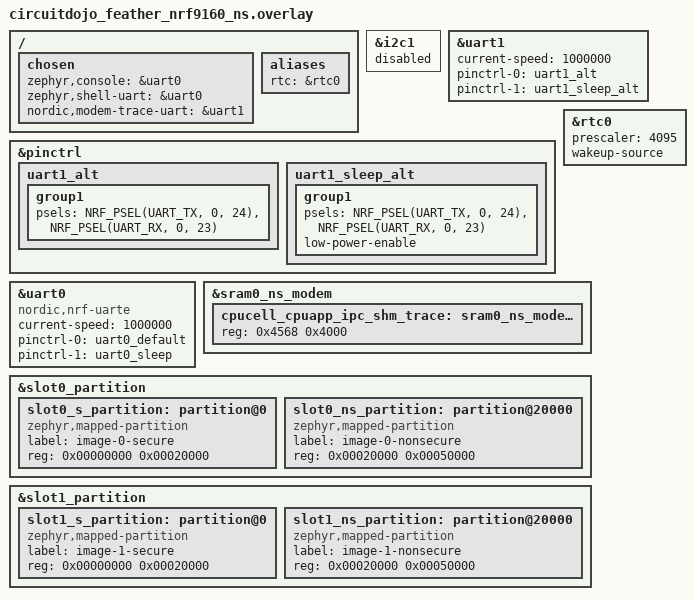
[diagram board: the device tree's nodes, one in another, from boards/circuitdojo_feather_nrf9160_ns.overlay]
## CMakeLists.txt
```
cmake_minimum_required(VERSION 3.20.0)

# This sample verifies the platform's certificate chain.
set(SAMPLE_TLS verify)
include(${CMAKE_CURRENT_SOURCE_DIR}/../common/app.cmake)

find_package(Zephyr REQUIRED HINTS $ENV{ZEPHYR_BASE})
project(https_init)

include(${CMAKE_CURRENT_SOURCE_DIR}/../common/cert.cmake)

target_sources(app PRIVATE src/main.c src/shadow.c)

include(${CMAKE_CURRENT_SOURCE_DIR}/../common/net.cmake)
```

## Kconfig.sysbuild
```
rsource "../Kconfig.sysbuild.signing"

# native_sim has no bootloader or second slot; every other board boots through
# MCUboot, which is where FOTA stages an image.
choice BOOTLOADER
	default BOOTLOADER_NONE if BOARD_NATIVE_SIM
	default BOOTLOADER_MCUBOOT
endchoice

source "share/sysbuild/Kconfig"
```

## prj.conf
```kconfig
# HTTPS connector, remote log upload and FOTA through MCUboot. The endpoint
# and token belong in the git-ignored prj.local.conf.
CONFIG_PIGEON=y
CONFIG_PIGEON_CONNECTOR_HTTPS=y
# The modem's credential store outlives a reflash and is keyed by tag, so each
# sample here owns a distinct one rather than the shared default.
CONFIG_PIGEON_HTTPS_SEC_TAG=42
CONFIG_PIGEON_LOG_UPLOAD=y
CONFIG_PIGEON_FOTA=y

# Image management, the path FOTA stages an image through.
CONFIG_BOOTLOADER_MCUBOOT=y
CONFIG_MCUBOOT_BOOTUTIL_LIB=y
CONFIG_FLASH=y
CONFIG_FLASH_MAP=y
CONFIG_FLASH_PAGE_LAYOUT=y
CONFIG_STREAM_FLASH=y
CONFIG_IMG_MANAGER=y
CONFIG_IMG_ERASE_PROGRESSIVELY=y
CONFIG_IMG_ENABLE_IMAGE_CHECK=y
CONFIG_SETTINGS=y

CONFIG_PICOLIBC=y
CONFIG_STD_C17=y
CONFIG_MISRA_SANE=y
CONFIG_DEBUG=y
CONFIG_DEBUG_OPTIMIZATIONS=y

CONFIG_HEAP_MEM_POOL_SIZE=8192
CONFIG_MAIN_STACK_SIZE=8192
CONFIG_SYSTEM_WORKQUEUE_STACK_SIZE=4096
# Logging from the connection manager's event callbacks overflows the default.
CONFIG_NET_MGMT_EVENT_STACK_SIZE=2048

CONFIG_NETWORKING=y
CONFIG_NET_SOCKETS=y
CONFIG_NET_SOCKETS_SOCKOPT_TLS=y
CONFIG_NET_IPV4=y
CONFIG_NET_IPV6=y
CONFIG_NET_CONNECTION_MANAGER=y
CONFIG_NET_CONNECTION_MANAGER_MONITOR_STACK_SIZE=1024

CONFIG_LOG=y
CONFIG_LOG_DEFAULT_LEVEL=3
CONFIG_LOG_MODE_IMMEDIATE=y
# Lets the shadow's "log" field silence and restore logging at runtime.
CONFIG_LOG_RUNTIME_FILTERING=y
CONFIG_NET_LOG=y
CONFIG_NET_SOCKETS_LOG_LEVEL_DBG=y
```

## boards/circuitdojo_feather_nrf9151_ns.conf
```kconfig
# nRF9151 Feather counterpart to circuitdojo_feather_nrf9160_ns.conf. Content
# is identical -- nothing here is 9160-specific (modem key mgmt, TF-M build
# mode, UART async config, modem trace backend selection, boot banner all
# apply the same way to any nRF91-series board using the modem-offloaded
# TLS + TF-M split), so this is a straight mirror of that file rather than a
# copy this board needed to diverge from.

# NCS boot banner
CONFIG_NCS_APPLICATION_BOOT_BANNER_STRING="Pigeon"

# Allow writing to the (internal) flash at runtime, needed for MCUmgr image
# management to write firmware updates into slot1.
CONFIG_MPU_ALLOW_FLASH_WRITE=y

# Align the max FD entry to NRF_MODEM_MAX_SOCKET_COUNT(8)
CONFIG_ZVFS_OPEN_MAX=8
CONFIG_NET_SOCKETS_POLL_MAX=8

# Disable Duplicate Address Detection (DAD)
# due to not being properly implemented for offloaded interfaces.
CONFIG_NET_IPV6_NBR_CACHE=n
CONFIG_NET_IPV6_MLD=n

# Connection Manager and Connectivity layer
CONFIG_NRF_MODEM_LIB_NET_IF=y

# AT Host
CONFIG_UART_INTERRUPT_DRIVEN=y
CONFIG_AT_HOST_LIBRARY=y

# Modem key management
# Must be y: nRF91 TLS sockets are offloaded to the modem, which does its own
# TLS handshake using certs provisioned to ITS OWN credential store via AT
# commands (modem_key_mgmt), not Zephyr's tls_credentials/mbedTLS subsystem.
# With this =n, connection_manager.c's provision_cert() fell through to
# tls_credential_add(), which the offloaded socket implementation never
# consults -- so the modem had no CA cert at the sec_tag and any outbound TLS
# connection (e.g. the pigeon HTTPS shadow fetch) would fail the handshake.
CONFIG_MODEM_KEY_MGMT=y

# TF-M configurations
# TF-M's secure image size/RAM (slot0_s_partition, sram0_s) is now set via the
# board devicetree overlay instead of Partition Manager Kconfig.
CONFIG_BUILD_WITH_TFM=y
CONFIG_TFM_PROFILE_TYPE_NOT_SET=y
CONFIG_TFM_CMAKE_BUILD_TYPE_RELEASE=y

# UART configuration (common)
CONFIG_SERIAL=y
CONFIG_UART_ASYNC_API=y

# UART configuration (nRF91 specific)
CONFIG_UART_1_ASYNC=y
CONFIG_UART_1_INTERRUPT_DRIVEN=n

# Modem trace uart backend
# NRF_MODEM_LIB_TRACE_BACKEND_UART lives under "if NRF_MODEM_LIB_TRACE", so the
# trace subsystem itself must be enabled or the backend choice never applies.
CONFIG_NRF_MODEM_LIB_TRACE=y
CONFIG_NRF_MODEM_LIB_TRACE_BACKEND_UART=y

# Keeps the MCUboot secondary/OTA slot non-secure at the SPU level, so a
# FOTA write from the non-secure app doesn't fault.
# This board's own devicetree (Circuit Dojo upstream) declares an onboard SPI-NOR
# chip via `nordic,pm-ext-flash = &w25q128jv` (for its littlefs partition, NOT
# MCUboot). That alone flips PM_EXTERNAL_FLASH_ENABLED=y, which flips this
# symbol's Kconfig default to y (nrf/subsys/partition_manager/Kconfig:
# `default y if BOOTLOADER_MCUBOOT`), which SKIPS the NRF_NS_SECONDARY=y
# auto-configuration in nrf/modules/trusted-firmware-m/CMakeLists.txt (guarded on
# `NOT PM_EXTERNAL_FLASH_MCUBOOT_SECONDARY`). With NRF_NS_SECONDARY off, TF-M
# leaves the ENTIRE secondary/OTA slot Secure at the SPU level, so the non-secure
# FOTA client's write to slot1 (0x80000) is a TrustZone attribution-unit
# violation -> Secure Fault -> halt. We do NOT put the MCUboot secondary slot in
# external flash (it's the same internal flash as slot0), so force this off. The
# 9160 doesn't need this: its board dtsi has no `nordic,pm-ext-flash`, so the
# Kconfig default never fires.
CONFIG_PM_EXTERNAL_FLASH_MCUBOOT_SECONDARY=n
```

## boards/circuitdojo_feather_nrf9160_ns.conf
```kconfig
# Beyond ../../common/boards/nrf91.conf.

# What this build reports as its running firmware; bump it with each release.
CONFIG_PIGEON_FOTA_CURRENT_VERSION="0.1.0"
# The nRF Connect SDK dfu_target backend, which the modem and MCUboot
# integration are built around.
CONFIG_PIGEON_FOTA_NCS=y

# FOTA resume and the attempt budget both persist state; without a backend
# behind CONFIG_SETTINGS they disappear from the build rather than fail it.
CONFIG_NVS=y
CONFIG_SETTINGS_NVS=y
# One shadow target is chased a bounded number of times, so an image that
# boot-loops cannot re-download itself forever.
CONFIG_PIGEON_FOTA_ATTEMPT_BUDGET=y

# Image upload over the console UART (newtmgr -c serial) as a FOTA fallback.
CONFIG_BASE64=y
CONFIG_CRC=y
CONFIG_ZCBOR=y
CONFIG_MCUMGR=y
CONFIG_UART_MCUMGR=y
CONFIG_MCUMGR_TRANSPORT_UART=y
CONFIG_MCUMGR_GRP_IMG=y
CONFIG_MCUMGR_GRP_OS=y

# Modem trace on uart1 (see the overlay); the backend choice only applies
# once the trace subsystem itself is on.
CONFIG_NRF_MODEM_LIB_TRACE=y
CONFIG_NRF_MODEM_LIB_TRACE_BACKEND_UART=y
CONFIG_UART_1_ASYNC=y
CONFIG_UART_1_INTERRUPT_DRIVEN=n
```

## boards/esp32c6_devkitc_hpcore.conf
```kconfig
# Beyond ../../common/boards/esp32c6.conf.

# What this build reports as its running firmware; bump it with each release.
# Here, not prj.conf: native_sim builds with FOTA off, and assigning a symbol
# whose dependencies are unmet fails the build.
CONFIG_PIGEON_FOTA_CURRENT_VERSION="0.1.0"

# One TLS connection per Range chunk costs about nine seconds here; 32 KiB
# chunks fetch an 800 KiB image in about 25 of them.
CONFIG_PIGEON_FOTA_CHUNK_SIZE=32768
# A long download can still fail a WiFi-adapter allocation inside a fatal
# ESP_ERROR_CHECK; a reboot there resumes from the persisted offset.
CONFIG_PIGEON_REBOOT_ON_FATAL=y
CONFIG_PIGEON_FOTA_RESUME=y
# One shadow target is chased a bounded number of times, so an image that
# boot-loops cannot re-download itself forever.
CONFIG_PIGEON_FOTA_ATTEMPT_BUDGET=y
# The resume offset and attempt count persist in settings over NVS.
CONFIG_MCUBOOT_IMG_MANAGER=y
CONFIG_NVS=y
CONFIG_SETTINGS_NVS=y
```

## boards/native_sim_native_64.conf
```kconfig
# Beyond ../../common/boards/native_sim.conf.

# No bootloader or second slot on the host, so no FOTA or image management.
CONFIG_PIGEON_FOTA=n
CONFIG_BOOTLOADER_MCUBOOT=n
CONFIG_MCUBOOT_BOOTUTIL_LIB=n
CONFIG_IMG_MANAGER=n
CONFIG_IMG_ERASE_PROGRESSIVELY=n
CONFIG_IMG_ENABLE_IMAGE_CHECK=n
```

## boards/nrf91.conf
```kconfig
# Both nRF91 Feathers, on top of ../../common/boards/nrf91.conf.

# What this build reports as its running firmware; bump it with each release.
# Here, not prj.conf: native_sim builds with FOTA off, and assigning a symbol
# whose dependencies are unmet fails the build.
CONFIG_PIGEON_FOTA_CURRENT_VERSION="0.1.0"
# The nRF Connect SDK dfu_target backend, which the modem and MCUboot
# integration are built around.
CONFIG_PIGEON_FOTA_NCS=y

# The nRF Connect SDK banner only exists where a VERSION file does, and it
# otherwise announces itself as "My Application".
CONFIG_NCS_APPLICATION_BOOT_BANNER_STRING="Pigeon"

# FOTA resume and the attempt budget both persist state; without a backend
# behind CONFIG_SETTINGS they disappear from the build rather than fail it.
CONFIG_NVS=y
CONFIG_SETTINGS_NVS=y
# One shadow target is chased a bounded number of times, so an image that
# boot-loops cannot re-download itself forever.
CONFIG_PIGEON_FOTA_ATTEMPT_BUDGET=y

# Modem trace on uart1 (see the overlay); the backend choice only applies
# once the trace subsystem itself is on.
CONFIG_NRF_MODEM_LIB_TRACE=y
CONFIG_NRF_MODEM_LIB_TRACE_BACKEND_UART=y
CONFIG_UART_1_ASYNC=y
CONFIG_UART_1_INTERRUPT_DRIVEN=n
```

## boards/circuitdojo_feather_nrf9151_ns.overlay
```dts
/* Modem trace UART; this board's own partition file already carves out the
 * trace buffer, and its i2c1 is disabled by default. */
&uart1 {
  status = "okay";
  current-speed = <1000000>;
};

&uart0 {
  status = "okay";
  compatible = "nordic,nrf-uarte";
  current-speed = <115200>;
  pinctrl-0 = <&uart0_default>;
  pinctrl-1 = <&uart0_sleep>;
  pinctrl-names = "default", "sleep";
};

/* The stock 256/192 KiB secure/non-secure split leaves TF-M most of its
 * share unused while this application overflows its own. The slot total is
 * unchanged, so MCUboot's overlay needs nothing. */
/delete-node/ &slot0_s_partition;
/delete-node/ &slot0_ns_partition;

&slot0_partition {
  slot0_s_partition: partition@0 {
    compatible = "zephyr,mapped-partition";
    label = "image-0-secure";
    reg = <0x00000000 0x00020000>;
  };

  slot0_ns_partition: partition@20000 {
    compatible = "zephyr,mapped-partition";
    label = "image-0-nonsecure";
    reg = <0x00020000 0x00050000>;
  };
};

/delete-node/ &slot1_s_partition;
/delete-node/ &slot1_ns_partition;

&slot1_partition {
  slot1_s_partition: partition@0 {
    compatible = "zephyr,mapped-partition";
    label = "image-1-secure";
    reg = <0x00000000 0x00020000>;
  };

  slot1_ns_partition: partition@20000 {
    compatible = "zephyr,mapped-partition";
    label = "image-1-nonsecure";
    reg = <0x00020000 0x00050000>;
  };
};

/ {
  chosen {
    zephyr,console = &uart0;
    zephyr,shell-uart = &uart0;
    nordic,modem-trace-uart = &uart1;
  };
};
```

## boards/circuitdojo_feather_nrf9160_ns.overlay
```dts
/* i2c1 shares its peripheral instance with the trace UART below. */
&i2c1 {
    status = "disabled";
};

/* Modem trace UART. */
&uart1 {
    status = "okay";
    current-speed = <1000000>;
    pinctrl-0 = <&uart1_alt>;
    pinctrl-1 = <&uart1_sleep_alt>;
    pinctrl-names = "default", "sleep";
};

&pinctrl {
    uart1_alt: uart1_alt {
        group1 {
            psels = <NRF_PSEL(UART_TX, 0, 24)>,
                <NRF_PSEL(UART_RX, 0, 23)>;
        };
    };

    uart1_sleep_alt: uart1_sleep_alt {
        group1 {
            psels = <NRF_PSEL(UART_TX, 0, 24)>,
                <NRF_PSEL(UART_RX, 0, 23)>;
            low-power-enable;
        };
    };
};

&uart0 {
  status = "okay";
  compatible = "nordic,nrf-uarte";
  current-speed = <1000000>;
  pinctrl-0 = <&uart0_default>;
  pinctrl-1 = <&uart0_sleep>;
  pinctrl-names = "default", "sleep";
};

&rtc0 {
  status = "okay";
  /* 32768 Hz / (4095 + 1) = 8 Hz. */
  prescaler = <4095>;
  wakeup-source;
};

/* The modem trace buffer fits in the slack the stock partition file leaves
 * inside the modem shared-memory region, so nothing else has to move.
 * Nordic's own modem-trace snippet sizes it for a different SRAM total and
 * overflows this board. */
&sram0_ns_modem {
  cpucell_cpuapp_ipc_shm_trace: sram0_ns_modem@4568 {
    reg = <0x4568 0x4000>;
  };
};

/* The stock 256/192 KiB secure/non-secure split leaves TF-M most of its
 * share unused while this application overflows its own. The slot total is
 * unchanged, so MCUboot's overlay needs nothing. */
/delete-node/ &slot0_s_partition;
/delete-node/ &slot0_ns_partition;

&slot0_partition {
  slot0_s_partition: partition@0 {
    compatible = "zephyr,mapped-partition";
    label = "image-0-secure";
    reg = <0x00000000 0x00020000>;
  };

  slot0_ns_partition: partition@20000 {
    compatible = "zephyr,mapped-partition";
    label = "image-0-nonsecure";
    reg = <0x00020000 0x00050000>;
  };
};

/delete-node/ &slot1_s_partition;
/delete-node/ &slot1_ns_partition;

&slot1_partition {
  slot1_s_partition: partition@0 {
    compatible = "zephyr,mapped-partition";
    label = "image-1-secure";
    reg = <0x00000000 0x00020000>;
  };

  slot1_ns_partition: partition@20000 {
    compatible = "zephyr,mapped-partition";
    label = "image-1-nonsecure";
    reg = <0x00020000 0x00050000>;
  };
};

/ {
  chosen {
    zephyr,console = &uart0;
    zephyr,shell-uart = &uart0;
    nordic,modem-trace-uart = &uart1;
  };

  aliases {
    rtc = &rtc0;
  };
};
```

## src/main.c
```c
#include <pigeon.h>
#include <zephyr/kernel.h>

#include "net_connect.h"
#include "shadow.h"

/* The platform's root CA, terminated because mbedTLS parses PEM as a string. */
static const char ca_cert[] = {
#include "GTS_Root_R4.crt.hex"
    0x00
};

BUILD_ASSERT(sizeof(ca_cert) < KB(4), "the modem's credential store caps a certificate at 4 KiB");

int main(void) {
  int err = net_prepare();

  if (err) {
    return err;
  }

  err = net_install_ca(CONFIG_PIGEON_HTTPS_SEC_TAG, ca_cert, sizeof(ca_cert));
  if (err) {
    return err;
  }

  err = net_connect();
  if (err) {
    return err;
  }

  /* The endpoint and token come from Kconfig. device_id only names this
   * device in its own logs; the platform identifies it by its token. */
  struct pigeon_config config = {
      .device_id = "pigeon-sample",
      .connector = {.type = PIGEON_CONNECTOR_HTTPS},
  };

  err = pigeon_init(&config);
  if (err) {
    net_disconnect();
    return err;
  }

  shadow_loop();

  return net_disconnect();
}
```

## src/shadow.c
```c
/** @headerfile shadow.h */
#include "shadow.h"

#include <pigeon.h>
#include <string.h>
#include <zephyr/data/json.h>
#include <zephyr/kernel.h>
#include <zephyr/logging/log.h>
#include <zephyr/logging/log_ctrl.h>
#include <zephyr/sys/printk.h>

#include "net_connect.h"

LOG_MODULE_REGISTER(shadow);

/* target_config is opaque JSON to the library; this application decides what
 * its keys mean. "firmware" decodes into the struct pigeon_fota_apply() takes. */
struct app_shadow_config {
  bool log;
  int telemetry_interval;
  bool reboot;
#if defined(CONFIG_PIGEON_FOTA)
  struct pigeon_fota_info firmware;
#endif
};

#if defined(CONFIG_PIGEON_FOTA)
static const struct json_obj_descr app_firmware_descr[] = {
    JSON_OBJ_DESCR_PRIM(struct pigeon_fota_info, version, JSON_TOK_STRING_BUF),
    JSON_OBJ_DESCR_PRIM(struct pigeon_fota_info, size, JSON_TOK_NUMBER),
    JSON_OBJ_DESCR_PRIM(struct pigeon_fota_info, sha256, JSON_TOK_STRING_BUF),
};
#endif

static const struct json_obj_descr app_shadow_config_descr[] = {
    JSON_OBJ_DESCR_PRIM(struct app_shadow_config, log, JSON_TOK_TRUE),
    JSON_OBJ_DESCR_PRIM(struct app_shadow_config, telemetry_interval, JSON_TOK_NUMBER),
    JSON_OBJ_DESCR_PRIM(struct app_shadow_config, reboot, JSON_TOK_TRUE),
#if defined(CONFIG_PIGEON_FOTA)
    JSON_OBJ_DESCR_OBJECT(struct app_shadow_config, firmware, app_firmware_descr),
#endif
};

/* Defaults applied before the first sync of a boot. Nothing persists across
 * reboots, so every boot re-applies the platform's target from here.
 * firmware.version starts at this build's own version, which is what lets a
 * freshly booted image report itself as converged with no bookkeeping. */
static struct app_shadow_config current_config = {
    .log = false,
    .telemetry_interval = 60,
    .reboot = false,
#if defined(CONFIG_PIGEON_FOTA)
    .firmware = {.version = CONFIG_PIGEON_FOTA_CURRENT_VERSION, .size = 0, .sha256 = ""},
#endif
};

/* One call covers every module, so the shadow's "log" field really silences
 * and restores output. */
static void set_all_log_levels(uint32_t level) {
  uint32_t module_count = log_src_cnt_get(Z_LOG_LOCAL_DOMAIN_ID);

  for (uint32_t i = 0; i < module_count; i++) {
    log_filter_set(NULL, Z_LOG_LOCAL_DOMAIN_ID, (int16_t)i, level);
  }
}

/* Both keys ride one telemetry POST. poll_count restarting at 1 doubles as a
 * reboot indicator on the dashboard. */
static void report_telemetry(void) {
  static unsigned int poll_count;
  char buf[21];

  snprintk(buf, sizeof(buf), "%lld", (long long)(k_uptime_get() / 1000));

  int err = pigeon_telemetry_set("uptime_s", buf);

  snprintk(buf, sizeof(buf), "%u", ++poll_count);

  if (!err) {
    err = pigeon_telemetry_set("poll_count", buf);
  }

  if (!err) {
    err = pigeon_telemetry_flush();
  }

  if (err) {
    LOG_WRN("Telemetry report failed: %d", err);
  }
}

int shadow_sync(void) {
  struct pigeon_shadow_doc doc;
  int err = pigeon_shadow_get(&doc);

  if (err) {
    LOG_ERR("Failed to fetch device shadow: %d", err);
    return err;
  }

  LOG_INF(
      "Shadow fetched: target_version=%d current_version=%d updated_at=%lld", doc.target_version,
      doc.current_version, doc.updated_at
  );

#if defined(CONFIG_PIGEON_FOTA)
  /* A successful fetch is this application's definition of a healthy boot.
   * Runs before the convergence check so a new image that lands already
   * converged is still confirmed; a no-op once confirmed. */
  pigeon_fota_confirm_boot();
#endif

  report_telemetry();

  if (doc.target_version == doc.current_version) {
    LOG_INF("Shadow already converged at version %d; nothing to apply", doc.current_version);
    return 0;
  }

  /* json_obj_parse() edits its input, and target_config only lives until the
   * next fetch. */
  char config_buf[CONFIG_PIGEON_SHADOW_CONFIG_MAX];

  strncpy(config_buf, doc.target_config, sizeof(config_buf) - 1);
  config_buf[sizeof(config_buf) - 1] = '\0';

  /* Keys absent from a partial update keep their current value. reboot is a
   * one-shot command and always starts false. */
  struct app_shadow_config target = current_config;
  target.reboot = false;

  int64_t decoded = json_obj_parse(
      config_buf, strlen(config_buf), app_shadow_config_descr, ARRAY_SIZE(app_shadow_config_descr),
      &target
  );

  if (decoded < 0) {
    LOG_ERR("Failed to parse shadow target_config '%s': %lld", doc.target_config, decoded);
    return (int)decoded;
  }

  if (target.log != current_config.log) {
    LOG_INF(
        "Shadow v%d: log %s -> %s", doc.target_version, current_config.log ? "true" : "false",
        target.log ? "true" : "false"
    );
    set_all_log_levels(target.log ? CONFIG_LOG_DEFAULT_LEVEL : LOG_LEVEL_NONE);
  }

  if (target.telemetry_interval != current_config.telemetry_interval) {
    LOG_INF(
        "Shadow v%d: telemetry_interval %d -> %d", doc.target_version,
        current_config.telemetry_interval, target.telemetry_interval
    );
  }

  current_config.log = target.log;
  current_config.telemetry_interval = target.telemetry_interval;

  LOG_INF(
      "Applied shadow v%d: log=%s telemetry_interval=%d", doc.target_version,
      current_config.log ? "true" : "false", current_config.telemetry_interval
  );

#if defined(CONFIG_PIGEON_FOTA)
  /* The library compares against this build's compiled-in version, not
   * current_config, so a "firmware" key absent from the update is a no-op. */
  bool firmware_applied = false;
  /* Set when the shadow named an image this poll did not end up running.
   * Convergence is what makes the next poll return early, so reporting it
   * would leave the platform showing converged while the device stays on the
   * old image and stops trying. */
  bool firmware_unconverged = false;

  if (!pigeon_fota_update_available(&target.firmware)) {
    /* Running what is offered, so release any budget still held against it and
     * let a later re-offer of the same version start full. */
    pigeon_fota_attempts_clear();
  } else if (!pigeon_fota_attempt_allowed(&target.firmware, doc.target_version)) {
    LOG_ERR(
        "FOTA: attempt budget spent for firmware %s at shadow v%d; not downloading it again "
        "until the shadow is written anew",
        target.firmware.version, doc.target_version
    );
    target.firmware = current_config.firmware;
    firmware_unconverged = true;
  } else {
    LOG_WRN(
        "Shadow v%d requests firmware %s (currently running %s); starting FOTA download",
        doc.target_version, target.firmware.version, CONFIG_PIGEON_FOTA_CURRENT_VERSION
    );

    int fota_err = pigeon_fota_apply(&target.firmware);

    if (fota_err) {
      LOG_ERR(
          "FOTA apply failed: %d; leaving current image running, will retry next poll", fota_err
      );
      /* The report below has to name the version still running. */
      target.firmware = current_config.firmware;
      firmware_unconverged = true;
    } else {
      LOG_WRN("FOTA: image staged; rebooting to let the new image report for itself");
      /* A staged image is not a booted one: the bootloader can still refuse
       * it, and the image that boots reports its own version on its first
       * poll. The cost is one poll cycle before the platform sees convergence. */
      firmware_unconverged = true;
      firmware_applied = true;
    }
  }
#endif

  /* Sized for the firmware object too, whose sha256 alone is 64 characters. */
  char report_buf[256];
  int encode_err = json_obj_encode_buf(
      app_shadow_config_descr, ARRAY_SIZE(app_shadow_config_descr), &current_config, report_buf,
      sizeof(report_buf)
  );
  /* The report always carries what is running. Only the version it is
   * reported at is held back, which is what leaves the shadow short of its
   * target. */
  int32_t report_version = doc.target_version;

#if defined(CONFIG_PIGEON_FOTA)
  if (firmware_unconverged) {
    report_version = doc.current_version;
    if (firmware_applied) {
      LOG_WRN(
          "Shadow v%d left unconverged: reporting at v%d as firmware %s, the version still "
          "running; the image being booted into reports its own on its first poll",
          doc.target_version, report_version, current_config.firmware.version
      );
    } else {
      LOG_WRN(
          "Shadow v%d left unconverged: still running firmware %s, reporting at v%d so the next "
          "poll retries",
          doc.target_version, current_config.firmware.version, report_version
      );
    }
  }
#endif

  if (encode_err) {
    LOG_ERR("Failed to encode current_config for shadow report: %d", encode_err);
  } else {
    int report_err = pigeon_shadow_report(report_version, report_buf);

    if (report_err) {
      LOG_WRN("Shadow report-back failed: %d", report_err);
    } else {
      LOG_INF("Reported current_config back to platform at v%d", report_version);
    }
  }

#if defined(CONFIG_PIGEON_FOTA)
  if (target.reboot && firmware_unconverged) {
    /* Convergence is the only record that this one-shot command ran, and the
     * report above withheld it, so obeying now would reboot on every poll
     * until the firmware target resolves. A shadow carrying both reboots
     * twice: into the new image, then once more for the command. */
    LOG_WRN(
        "Shadow v%d requested reboot; deferring it until the firmware target resolves",
        doc.target_version
    );
    target.reboot = false;
  }
#endif

  /* "reboot" is a command, not state: kept out of current_config so it is
   * never seen as unchanged and re-run on every poll. net_disconnect() comes
   * first because a modem reset without a graceful power-off trips its
   * reset-loop protection. */
  if (target.reboot) {
    LOG_WRN("Shadow v%d requested reboot; disconnecting and rebooting now", doc.target_version);
    net_disconnect();
    pigeon_reboot();
  }

#if defined(CONFIG_PIGEON_FOTA)
  if (firmware_applied) {
    LOG_WRN(
        "FOTA: disconnecting and rebooting into newly staged firmware %s", target.firmware.version
    );
    net_disconnect();
    pigeon_reboot();
  }
#endif

  return 0;
}

void shadow_loop(void) {
  while (1) {
    shadow_sync();

    LOG_INF("Next shadow poll in %d s", current_config.telemetry_interval);
    k_sleep(K_SECONDS(current_config.telemetry_interval));
  }
}
```
